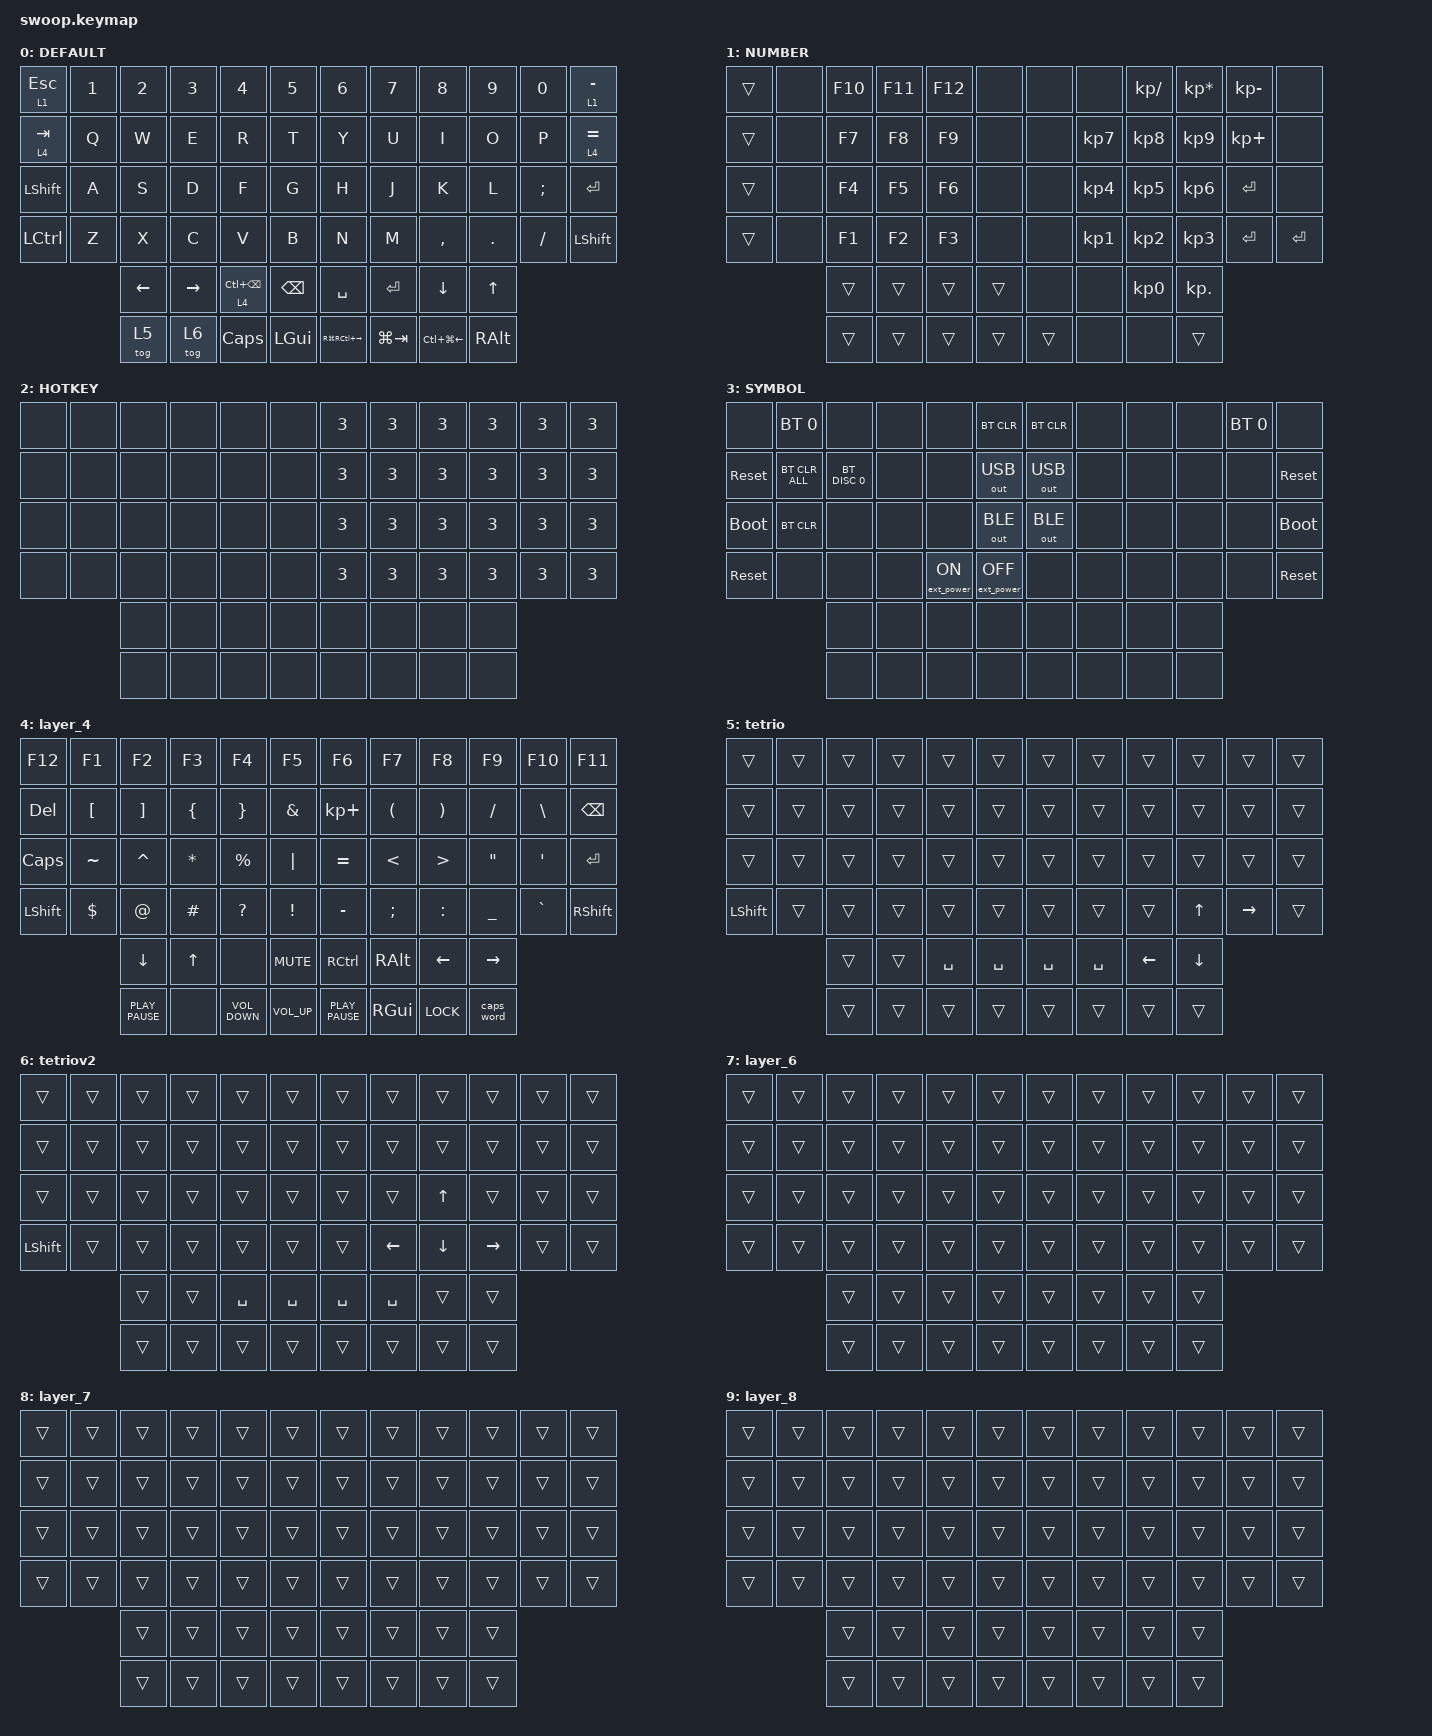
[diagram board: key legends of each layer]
#define ZMK_POINTING_DEFAULT_MOVE_VAL 800  // default: 600
#define ZMK_POINTING_DEFAULT_SCRL_VAL 15    // default: 10

#include <behaviors.dtsi>
#include <dt-bindings/zmk/bt.h>
#include <dt-bindings/zmk/ext_power.h>
#include <dt-bindings/zmk/keys.h>
#include <dt-bindings/zmk/outputs.h>
#include <dt-bindings/zmk/pointing.h>

#define DEFAULT 0
#define NUMBER  1
#define SYMBOL  2
#define HOTKEY  3

#define AS(keycode) &as LS(keycode) keycode

&lt {
    tapping-term-ms = <200>;
    flavor = "balanced";
    quick-tap-ms = <170>;
};

&mmv {
    x-input-code = <INPUT_REL_X>;
    y-input-code = <INPUT_REL_Y>;
    time-to-max-speed-ms = <300>;
    acceleration-exponent = <1>;
};

&msc {
    x-input-code = <INPUT_REL_HWHEEL>;
    y-input-code = <INPUT_REL_WHEEL>;
    time-to-max-speed-ms = <300>;
    acceleration-exponent = <0>;
};

/ {
    behaviors {
        td0: tap_dance_0 {
            compatible = "zmk,behavior-tap-dance";
            label = "L_CLK";
            #binding-cells = <0>;
            tapping-term-ms = <200>;
            bindings = <&mkp LCLK>, <&mkp LCLK>;
        };

        td1: tap_dance_1 {
            compatible = "zmk,behavior-tap-dance";
            label = "M_CLK";
            #binding-cells = <0>;
            tapping-term-ms = <200>;
            bindings = <&mkp MCLK>, <&mkp MCLK>;
        };

        td2: tap_dance_2 {
            compatible = "zmk,behavior-tap-dance";
            label = "R_CLK";
            #binding-cells = <0>;
            tapping-term-ms = <200>;
            bindings = <&mkp RCLK>, <&mkp RCLK>;
        };
    };

    behaviors {
        as: auto_shift {
            compatible = "zmk,behavior-hold-tap";
            label = "AUTO_SHIFT";
            #binding-cells = <2>;
            tapping-term-ms = <200>;
            quick-tap-ms = <0>;
            flavor = "tap-preferred";
            bindings = <&kp>, <&kp>;
        };

        modcp: mod_copy {
            compatible = "zmk,behavior-mod-morph";
            label = "MOD_COPY";
            #binding-cells = <0>;
            bindings = <&as LS(C) C>, <&kp C>;

            mods = <(LGUI | RGUI)>;
        };
    };

    keymap {
        compatible = "zmk,keymap";

        default_layer {
            label = "DEFAULT";
            bindings = <
&lt 1 ESC  &kp N1  &kp N2          &kp N3     &kp N4               &kp N5         &kp N6             &kp N7       &kp N8                  &kp N9         &kp N0    &lt 1 MINUS
&lt 4 TAB  &kp Q   &kp W           &kp E      &kp R                &kp T          &kp Y              &kp U        &kp I                   &kp O          &kp P     &lt 4 EQUAL
&kp LSHFT  &kp A   &kp S           &kp D      &kp F                &kp G          &kp H              &kp J        &kp K                   &kp L          &kp SEMI  &kp ENTER
&kp LCTRL  &kp Z   &kp X           &kp C      &kp V                &kp B          &kp N              &kp M        &kp COMMA               &kp DOT        &kp FSLH  &kp LSHFT
                   &kp LEFT_ARROW  &kp RIGHT  &lt 4 LC(BACKSPACE)  &kp BACKSPACE  &kp SPACE          &kp ENTER    &kp DOWN                &kp UP_ARROW
                   &tog 5          &tog 6     &kp CAPS             &kp LEFT_GUI   &kp RG(RC(RIGHT))  &kp LG(TAB)  &kp LC(LG(LEFT_ARROW))  &kp RIGHT_ALT
            >;
        };

        number_layer {
            label = "NUMBER";
            bindings = <
&trans  &none  &kp F10  &kp F11  &kp F12  &none   &none   &none      &kp KP_SLASH  &kp KP_MULTIPLY  &kp KP_MINUS  &none
&trans  &none  &kp F7   &kp F8   &kp F9   &none   &none   &kp KP_N7  &kp KP_N8     &kp KP_N9        &kp KP_PLUS   &none
&trans  &none  &kp F4   &kp F5   &kp F6   &none   &none   &kp KP_N4  &kp KP_N5     &kp KP_N6        &kp ENTER     &none
&trans  &none  &kp F1   &kp F2   &kp F3   &none   &none   &kp KP_N1  &kp KP_N2     &kp KP_N3        &kp ENTER     &kp ENTER
               &trans   &trans   &trans   &trans  &none   &none      &kp KP_N0     &kp KP_DOT
               &trans   &trans   &trans   &trans  &trans  &none      &none         &trans
            >;
        };

        hotkey_layer {
            label = "HOTKEY";
            bindings = <
&none  &none  &none  &none  &none  &none  &kp N3  &kp N3  &kp N3  &kp N3  &kp N3  &kp N3
&none  &none  &none  &none  &none  &none  &kp N3  &kp N3  &kp N3  &kp N3  &kp N3  &kp N3
&none  &none  &none  &none  &none  &none  &kp N3  &kp N3  &kp N3  &kp N3  &kp N3  &kp N3
&none  &none  &none  &none  &none  &none  &kp N3  &kp N3  &kp N3  &kp N3  &kp N3  &kp N3
              &none  &none  &none  &none  &none   &none   &none   &none
              &none  &none  &none  &none  &none   &none   &none   &none
            >;
        };

        symbol_layer {
            label = "SYMBOL";
            bindings = <
&none        &bt BT_SEL 0    &none          &none  &none             &bt BT_CLR         &bt BT_CLR    &none  &none  &none  &bt BT_SEL 0  &none
&sys_reset   &bt BT_CLR_ALL  &bt BT_DISC 0  &none  &none             &out OUT_USB       &out OUT_USB  &none  &none  &none  &none         &sys_reset
&bootloader  &bt BT_CLR      &none          &none  &none             &out OUT_BLE       &out OUT_BLE  &none  &none  &none  &none         &bootloader
&sys_reset   &none           &none          &none  &ext_power EP_ON  &ext_power EP_OFF  &none         &none  &none  &none  &none         &sys_reset
                             &none          &none  &none             &none              &none         &none  &none  &none
                             &none          &none  &none             &none              &none         &none  &none  &none
            >;
        };

        layer_4 {
            bindings = <
&kp F12         &kp F1            &kp F2             &kp F3          &kp F4             &kp F5           &kp F6             &kp F7                &kp F8                 &kp F9             &kp F10           &kp F11
&kp DEL         &kp LEFT_BRACKET  &kp RIGHT_BRACKET  &kp LEFT_BRACE  &kp RIGHT_BRACE    &kp AMPERSAND    &kp KP_PLUS        &kp LEFT_PARENTHESIS  &kp RIGHT_PARENTHESIS  &kp SLASH          &kp BACKSLASH     &kp BACKSPACE
&kp CAPSLOCK    &kp TILDE         &kp CARET          &kp ASTRK       &kp PERCENT        &kp PIPE         &kp EQUAL          &kp LESS_THAN         &kp GREATER_THAN       &kp DOUBLE_QUOTES  &kp SINGLE_QUOTE  &kp ENTER
&kp LEFT_SHIFT  &kp DOLLAR        &kp AT_SIGN        &kp HASH        &kp QUESTION       &kp EXCLAMATION  &kp MINUS          &kp SEMI              &kp COLON              &kp UNDER          &kp GRAVE         &kp RSHIFT
                                  &kp DOWN_ARROW     &kp UP_ARROW    &none              &kp K_MUTE       &kp RIGHT_CONTROL  &kp RIGHT_ALT         &kp LEFT               &kp RIGHT
                                  &kp K_PLAY_PAUSE   &none           &kp C_VOLUME_DOWN  &kp C_VOLUME_UP  &kp K_PLAY_PAUSE   &kp RIGHT_GUI         &kp K_LOCK             &caps_word
            >;
        };

        tetrio {
            bindings = <
&trans          &trans  &trans  &trans  &trans     &trans     &trans     &trans     &trans          &trans          &trans     &trans
&trans          &trans  &trans  &trans  &trans     &trans     &trans     &trans     &trans          &trans          &trans     &trans
&trans          &trans  &trans  &trans  &trans     &trans     &trans     &trans     &trans          &trans          &trans     &trans
&kp LEFT_SHIFT  &trans  &trans  &trans  &trans     &trans     &trans     &trans     &trans          &kp UP_ARROW    &kp RIGHT  &trans
                        &trans  &trans  &kp SPACE  &kp SPACE  &kp SPACE  &kp SPACE  &kp LEFT_ARROW  &kp DOWN_ARROW
                        &trans  &trans  &trans     &trans     &trans     &trans     &trans          &trans
            >;
        };

        tetriov2 {
            bindings = <
&trans          &trans  &trans  &trans  &trans     &trans     &trans     &trans     &trans          &trans     &trans  &trans
&trans          &trans  &trans  &trans  &trans     &trans     &trans     &trans     &trans          &trans     &trans  &trans
&trans          &trans  &trans  &trans  &trans     &trans     &trans     &trans     &kp UP_ARROW    &trans     &trans  &trans
&kp LEFT_SHIFT  &trans  &trans  &trans  &trans     &trans     &trans     &kp LEFT   &kp DOWN_ARROW  &kp RIGHT  &trans  &trans
                        &trans  &trans  &kp SPACE  &kp SPACE  &kp SPACE  &kp SPACE  &trans          &trans
                        &trans  &trans  &trans     &trans     &trans     &trans     &trans          &trans
            >;
        };

        layer_6 {
            bindings = <
&trans  &trans  &trans  &trans  &trans  &trans  &trans  &trans  &trans  &trans  &trans  &trans
&trans  &trans  &trans  &trans  &trans  &trans  &trans  &trans  &trans  &trans  &trans  &trans
&trans  &trans  &trans  &trans  &trans  &trans  &trans  &trans  &trans  &trans  &trans  &trans
&trans  &trans  &trans  &trans  &trans  &trans  &trans  &trans  &trans  &trans  &trans  &trans
                &trans  &trans  &trans  &trans  &trans  &trans  &trans  &trans
                &trans  &trans  &trans  &trans  &trans  &trans  &trans  &trans
            >;
        };

        layer_7 {
            bindings = <
&trans  &trans  &trans  &trans  &trans  &trans  &trans  &trans  &trans  &trans  &trans  &trans
&trans  &trans  &trans  &trans  &trans  &trans  &trans  &trans  &trans  &trans  &trans  &trans
&trans  &trans  &trans  &trans  &trans  &trans  &trans  &trans  &trans  &trans  &trans  &trans
&trans  &trans  &trans  &trans  &trans  &trans  &trans  &trans  &trans  &trans  &trans  &trans
                &trans  &trans  &trans  &trans  &trans  &trans  &trans  &trans
                &trans  &trans  &trans  &trans  &trans  &trans  &trans  &trans
            >;
        };

        layer_8 {
            bindings = <
&trans  &trans  &trans  &trans  &trans  &trans  &trans  &trans  &trans  &trans  &trans  &trans
&trans  &trans  &trans  &trans  &trans  &trans  &trans  &trans  &trans  &trans  &trans  &trans
&trans  &trans  &trans  &trans  &trans  &trans  &trans  &trans  &trans  &trans  &trans  &trans
&trans  &trans  &trans  &trans  &trans  &trans  &trans  &trans  &trans  &trans  &trans  &trans
                &trans  &trans  &trans  &trans  &trans  &trans  &trans  &trans
                &trans  &trans  &trans  &trans  &trans  &trans  &trans  &trans
            >;
        };
    };
};
